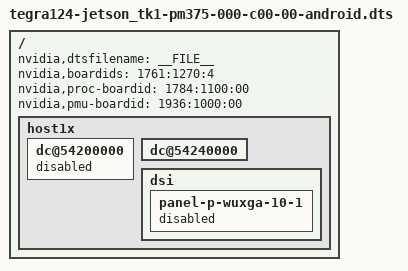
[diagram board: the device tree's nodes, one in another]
#include "tegra124-jetson_tk1-pm375-000-c00-00.dts"

/ {
	nvidia,dtsfilename = __FILE__;

	nvidia,boardids = "1761:1270:4";
	nvidia,proc-boardid = "1784:1100:00";
	nvidia,pmu-boardid = "1936:1000:00";

	host1x {
		/* tegradc.0 */
		dc@54200000 {
			status = "disabled";
		};
		/* tegradc.1 */
		dc@54240000 {
			status = "okay";
		};
		dsi {
			panel-p-wuxga-10-1 {
				status = "disabled";
			};
		};
        };
};
